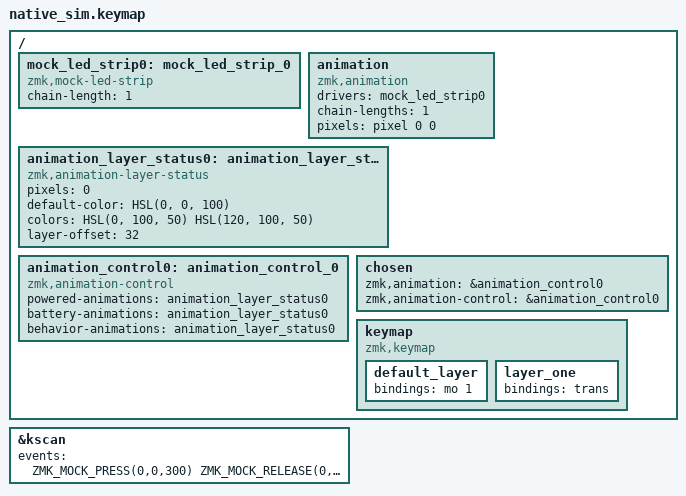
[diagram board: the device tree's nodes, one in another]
#include "../test.dtsi"
#include <dt-bindings/zmk/keys.h>
#include <dt-bindings/zmk/kscan_mock.h>
#include <zmk_driver_animation/animation.dtsi>
#include <dt-bindings/zmk_driver_animation/animation_control.h>

/*
 * Regression test for the BIT(idx) undefined-behavior bug in
 * animations/layer_status.c's render_frame: `layer-offset` here is set to
 * 32, so pixels[0]'s `idx = 0 + layer_offset` is 32 - equal to the bit
 * width of `data->layer_status` (a uint32_t), so `BIT(idx)` would shift by
 * an amount equal to the type's width, which is undefined behavior (unlike
 * the `colors[idx]` access a few lines later, which was already correctly
 * guarded by `idx < config->colors_size`).
 *
 * `data->layer_status` can never actually have bit 32 (or higher) set -
 * ZMK's real layer count is well under 32 - so the only behaviors a fix can
 * produce are "pixel stays inactive/black" (correct - out-of-range layer
 * indices can't be active) or a crash/garbage read (the bug). This test
 * toggles layer 1 active via `&mo 1` (exactly like tests/layer_status) and
 * asserts pixels[0] stays black throughout, proving the out-of-range index
 * is handled safely rather than crashing native_sim or reading garbage.
 */

/ {
    mock_led_strip0: mock_led_strip_0 {
        compatible = "zmk,mock-led-strip";
        chain-length = <1>;
    };

    animation: animation {
        compatible = "zmk,animation";
        drivers = <&mock_led_strip0>;
        chain-lengths = <1>;
        pixels = <&pixel 0 0>;
    };

    animation_layer_status0: animation_layer_status_0 {
        compatible = "zmk,animation-layer-status";
        pixels = <0>;
        default-color = <HSL(0, 0, 100)>;
        colors = <HSL(0, 100, 50) HSL(120, 100, 50)>;
        layer-offset = <32>;
    };

    animation_control0: animation_control_0 {
        compatible = "zmk,animation-control";
        powered-animations = <&animation_layer_status0>;
        battery-animations = <&animation_layer_status0>;
        behavior-animations = <&animation_layer_status0>;
    };

    chosen {
        zmk,animation = &animation_control0;
        zmk,animation-control = &animation_control0;
    };

    keymap {
        compatible = "zmk,keymap";

        default_layer {
            bindings = <
            &mo 1
            >;
        };

        layer_one {
            bindings = <
            &trans
            >;
        };
    };
};

&kscan {
    events = <
    ZMK_MOCK_PRESS(0,0,300)
    ZMK_MOCK_RELEASE(0,0,300)
    >;
};
